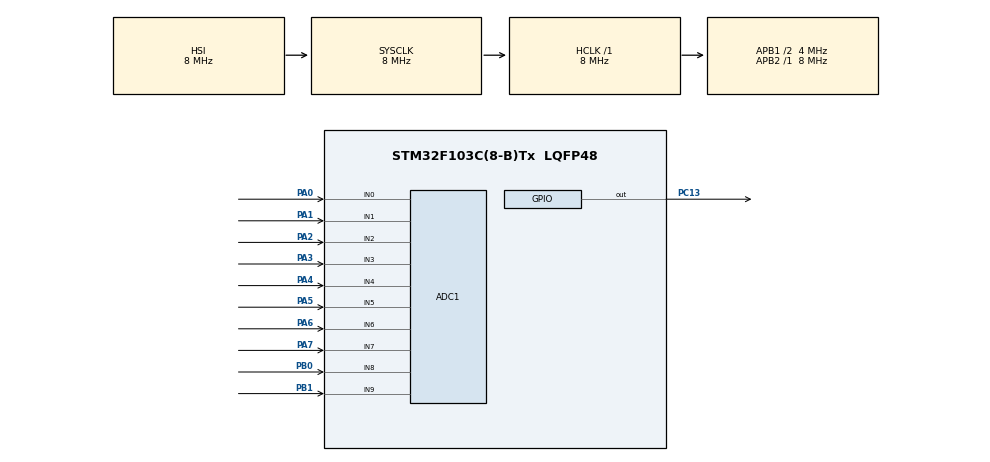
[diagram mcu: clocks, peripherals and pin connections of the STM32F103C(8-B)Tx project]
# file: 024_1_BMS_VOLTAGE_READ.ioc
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ADC1.Channel-2\#ChannelRegularConversion=ADC_CHANNEL_1
ADC1.ContinuousConvMode=ENABLE
ADC1.NbrOfConversionFlag=1
ADC1.Rank-2\#ChannelRegularConversion=1
ADC1.SamplingTime-2\#ChannelRegularConversion=ADC_SAMPLETIME_7CYCLES_5
ADC1.master=1
Mcu.Family=STM32F1
Mcu.Name=STM32F103C(8-B)Tx
Mcu.Package=LQFP48
NVIC.PriorityGroup=NVIC_PRIORITYGROUP_4
PA0-WKUP.Signal=ADCx_IN0
PA1.Signal=ADCx_IN1
PA13.Mode=Serial_Wire
PA13.Signal=SYS_JTMS-SWDIO
PA14.Mode=Serial_Wire
PA14.Signal=SYS_JTCK-SWCLK
PA2.Signal=ADCx_IN2
PA3.Signal=ADCx_IN3
PA4.Signal=ADCx_IN4
PA5.Signal=ADCx_IN5
PA6.Signal=ADCx_IN6
PA7.Signal=ADCx_IN7
PB0.Signal=ADCx_IN8
PB1.Signal=ADCx_IN9
PC13-TAMPER-RTC.Signal=GPIO_Output
ProjectManager.HeapSize=0x200
ProjectManager.StackSize=0x400
ProjectManager.TargetToolchain=STM32CubeIDE
RCC.ADCPresc=RCC_ADCPCLK2_DIV6
RCC.AHBFreq_Value=8000000
RCC.APB1CLKDivider=RCC_HCLK_DIV2
RCC.APB1Freq_Value=4000000
RCC.APB1TimFreq_Value=8000000
RCC.APB2Freq_Value=8000000
RCC.APB2TimFreq_Value=8000000
RCC.HCLKFreq_Value=8000000
RCC.PLLMUL=RCC_PLL_MUL9
RCC.PLLSourceVirtual=RCC_PLLSOURCE_HSE
RCC.SYSCLKFreq_VALUE=8000000
RCC.USBFreq_Value=72000000
SH.ADCx_IN0.0=ADC1_IN0,IN0
SH.ADCx_IN1.0=ADC1_IN1,IN1
SH.ADCx_IN2.0=ADC1_IN2,IN2
SH.ADCx_IN3.0=ADC1_IN3,IN3
SH.ADCx_IN4.0=ADC1_IN4,IN4
SH.ADCx_IN5.0=ADC1_IN5,IN5
SH.ADCx_IN6.0=ADC1_IN6,IN6
SH.ADCx_IN7.0=ADC1_IN7,IN7
SH.ADCx_IN8.0=ADC1_IN8,IN8
SH.ADCx_IN9.0=ADC1_IN9,IN9
board=custom

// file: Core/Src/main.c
/* USER CODE BEGIN Header */
/**
  ******************************************************************************
  * @file           : main.c
  * @brief          : Main program body
  ******************************************************************************
  * @attention
  *
  * <h2><center>&copy; Copyright (c) 2021 STMicroelectronics.
  * All rights reserved.</center></h2>
  *
  * This software component is licensed by ST under BSD 3-Clause license,
  * the "License"; You may not use this file except in compliance with the
  * License. You may obtain a copy of the License at:
  *                        opensource.org/licenses/BSD-3-Clause
  *
  ******************************************************************************
  */
/* USER CODE END Header */
#include "main.h"

ADC_HandleTypeDef hadc1;

/* USER CODE BEGIN PV */

float VCEL1;
uint16_t cel1_adc;

/* USER CODE END PV */

void SystemClock_Config(void);
static void MX_GPIO_Init(void);
static void MX_ADC1_Init(void);

/* USER CODE BEGIN 0 */

void Read_ADC()
{
	HAL_ADC_Start(&hadc1);
	if(HAL_ADC_PollForConversion(&hadc1,100000) == HAL_OK)
		cel1_adc = HAL_ADC_GetValue(&hadc1);
	HAL_ADC_Stop(&hadc1);

}

/* USER CODE END 0 */

int main(void)
{

  /* MCU Configuration--------------------------------------------------------*/

  /* Reset of all peripherals, Initializes the Flash interface and the Systick. */
  HAL_Init();

  /* Configure the system clock */
  SystemClock_Config();

  /* Initialize all configured peripherals */
  MX_GPIO_Init();
  MX_ADC1_Init();

  /* Infinite loop */
  /* USER CODE BEGIN WHILE */
  while (1)
  {
	  Read_ADC();
	  VCEL1 = cel1_adc*(3.3/4095);
	  HAL_GPIO_TogglePin(GPIOD, GPIO_PIN_13);
	  HAL_Delay(250);
    /* USER CODE END WHILE */

  }
}

void SystemClock_Config(void)
{
  RCC_OscInitTypeDef RCC_OscInitStruct = {0};
  RCC_ClkInitTypeDef RCC_ClkInitStruct = {0};
  RCC_PeriphCLKInitTypeDef PeriphClkInit = {0};

  /** Initializes the RCC Oscillators according to the specified parameters
  * in the RCC_OscInitTypeDef structure.
  */
  RCC_OscInitStruct.OscillatorType = RCC_OSCILLATORTYPE_HSI;
  RCC_OscInitStruct.HSIState = RCC_HSI_ON;
  RCC_OscInitStruct.HSICalibrationValue = RCC_HSICALIBRATION_DEFAULT;
  RCC_OscInitStruct.PLL.PLLState = RCC_PLL_NONE;
  if (HAL_RCC_OscConfig(&RCC_OscInitStruct) != HAL_OK)
  {
    Error_Handler();
  }
  /** Initializes the CPU, AHB and APB buses clocks
  */
  RCC_ClkInitStruct.ClockType = RCC_CLOCKTYPE_HCLK|RCC_CLOCKTYPE_SYSCLK
                              |RCC_CLOCKTYPE_PCLK1|RCC_CLOCKTYPE_PCLK2;
  RCC_ClkInitStruct.SYSCLKSource = RCC_SYSCLKSOURCE_HSI;
  RCC_ClkInitStruct.AHBCLKDivider = RCC_SYSCLK_DIV1;
  RCC_ClkInitStruct.APB1CLKDivider = RCC_HCLK_DIV2;
  RCC_ClkInitStruct.APB2CLKDivider = RCC_HCLK_DIV1;

  if (HAL_RCC_ClockConfig(&RCC_ClkInitStruct, FLASH_LATENCY_0) != HAL_OK)
  {
    Error_Handler();
  }
  PeriphClkInit.PeriphClockSelection = RCC_PERIPHCLK_ADC;
  PeriphClkInit.AdcClockSelection = RCC_ADCPCLK2_DIV6;
  if (HAL_RCCEx_PeriphCLKConfig(&PeriphClkInit) != HAL_OK)
  {
    Error_Handler();
  }
}

static void MX_ADC1_Init(void)
{

  ADC_ChannelConfTypeDef sConfig = {0};

  /** Common config
  */
  hadc1.Instance = ADC1;
  hadc1.Init.ScanConvMode = ADC_SCAN_DISABLE;
  hadc1.Init.ContinuousConvMode = ENABLE;
  hadc1.Init.DiscontinuousConvMode = DISABLE;
  hadc1.Init.ExternalTrigConv = ADC_SOFTWARE_START;
  hadc1.Init.DataAlign = ADC_DATAALIGN_RIGHT;
  hadc1.Init.NbrOfConversion = 1;
  if (HAL_ADC_Init(&hadc1) != HAL_OK)
  {
    Error_Handler();
  }
  /** Configure Regular Channel
  */
  sConfig.Channel = ADC_CHANNEL_1;
  sConfig.Rank = ADC_REGULAR_RANK_1;
  sConfig.SamplingTime = ADC_SAMPLETIME_7CYCLES_5;
  if (HAL_ADC_ConfigChannel(&hadc1, &sConfig) != HAL_OK)
  {
    Error_Handler();
  }

}

static void MX_GPIO_Init(void)
{
  GPIO_InitTypeDef GPIO_InitStruct = {0};

  /* GPIO Ports Clock Enable */
  __HAL_RCC_GPIOC_CLK_ENABLE();
  __HAL_RCC_GPIOA_CLK_ENABLE();
  __HAL_RCC_GPIOB_CLK_ENABLE();

  /*Configure GPIO pin Output Level */
  HAL_GPIO_WritePin(GPIOC, GPIO_PIN_13, GPIO_PIN_RESET);

  /*Configure GPIO pin : PC13 */
  GPIO_InitStruct.Pin = GPIO_PIN_13;
  GPIO_InitStruct.Mode = GPIO_MODE_OUTPUT_PP;
  GPIO_InitStruct.Pull = GPIO_NOPULL;
  GPIO_InitStruct.Speed = GPIO_SPEED_FREQ_LOW;
  HAL_GPIO_Init(GPIOC, &GPIO_InitStruct);

}

void Error_Handler(void)
{
  __disable_irq();
  while (1)
  {
  }
}

/************************ (C) COPYRIGHT STMicroelectronics *****END OF FILE****/
